# ESP32S31_RADIO register map
Vendor: Espressif; Series: ESP32-S31; File version: 3.52
Registers are 32-bit, read-write, no defined reset value unless marked. A register's access mark holds for its fields unless they carry their own. Offsets are from the block's base; [hi:lo] are bit positions.

## PHY_AGC_ORACLE — OPAQUE PHY AGC, PBus-pulse, antenna, RX-compensation, DC-memory, post-initialization and 11b-control registers recovered from complete, finite rev0 ROM/blob bodies. One physical register has one identity even when independent bodies prove different fields. Names describe their proven operation role, not an unevidenced electrical identity.
Base 0x20100000
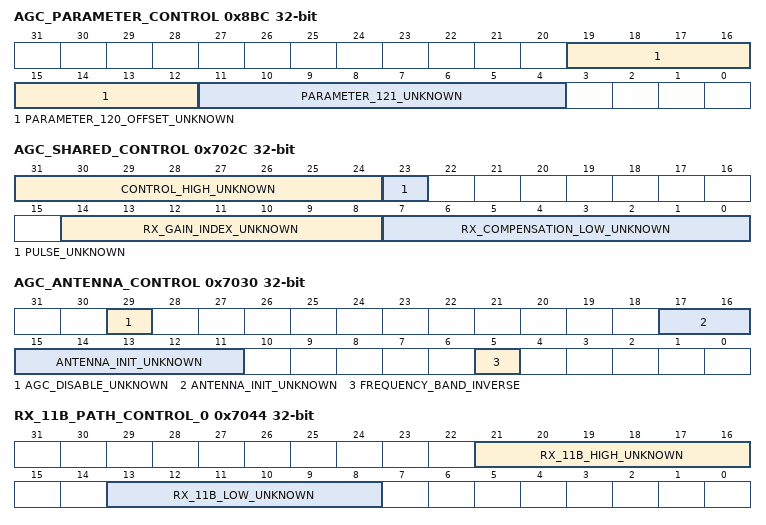
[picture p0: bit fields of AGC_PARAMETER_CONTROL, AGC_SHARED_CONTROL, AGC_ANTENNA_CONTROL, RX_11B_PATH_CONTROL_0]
0x8BC AGC_PARAMETER_CONTROL — Complete phy_agc_reg_init performs two fresh-read parameter-derived field replacements.
  [19:12] PARAMETER_120_OFFSET_UNKNOWN — Second update writes the low eight bits of parameter byte 0x120 plus 0x50 into bits 19:12.
  [11:4] PARAMETER_121_UNKNOWN — First update writes parameter byte 0x121 into bits 11:4.
0x702C AGC_SHARED_CONTROL — Shared word updated by complete phy_agc_reg_init, phy_enable_agc, phy_pbus_force_mode, phy_force_rx_gain, phy_set_rx_comp_new, and the final limit tail of phy_set_rx_gain_table.
  [31:24] CONTROL_HIGH_UNKNOWN — Complete phy_agc_reg_init and the delayed phy_pbus_force_mode tail write 0x32 into bits 31:24 before pulsing bit 23; complete phy_force_rx_gain retains its second argument to this byte without rejecting any representable image.
  [23] PULSE_UNKNOWN — Bit 23 is pulsed by complete phy_enable_agc and by the delayed tail of phy_pbus_force_mode; complete phy_force_rx_gain replaces it with the caller low bit.
  [14:8] RX_GAIN_INDEX_UNKNOWN — Bits 14:8 receive parameter byte 0x121 during AGC initialization and the final Wi-Fi RX gain index after table publication.
  [7:0] RX_COMPENSATION_LOW_UNKNOWN — Complete phy_set_rx_comp_new writes 0xed into bits 7:0.
0x7030 AGC_ANTENNA_CONTROL — Shared word updated independently by complete AGC enable/disable, antenna initialization and frequency-band selection bodies.
  [29] AGC_DISABLE_UNKNOWN — Instruction-exact AGC disable/enable gate.
  [17:11] ANTENNA_INIT_UNKNOWN — Complete phy_ant_init writes 0x34 into bits 17:11.
  [5] FREQUENCY_BAND_INVERSE — Complete phy_freq_band_reg_set writes the inverse of the caller low bit.
0x703C DC_MEMORY_CONTROL — Complete phy_dc_mem_clr sets then clears bit 20 using a fresh read before each write.
  [20] CLEAR_PULSE_UNKNOWN — Instruction-exact set/clear pulse; the vendor symbol qualifies the operation while the electrical effect remains unknown.
0x7044 RX_11B_PATH_CONTROL_0 — Complete phy_bb_agc_reg_update writes the full word; complete phy_rx_11b_opt later replaces two six-bit fields.
  [21:16] RX_11B_HIGH_UNKNOWN — Complete phy_rx_11b_opt replaces bits 21:16.
  [13:8] RX_11B_LOW_UNKNOWN — Complete phy_rx_11b_opt replaces bits 13:8.
0x7048 AGC_UPDATE_7048_OPAQUE wo — Complete phy_bb_agc_reg_update writes 0xff7da4f3.
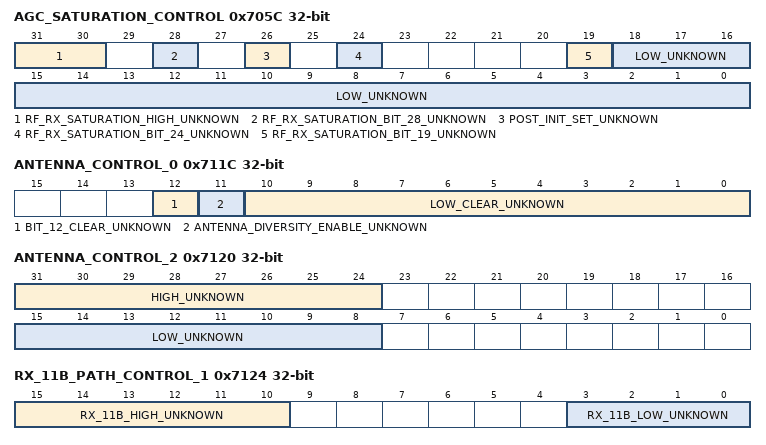
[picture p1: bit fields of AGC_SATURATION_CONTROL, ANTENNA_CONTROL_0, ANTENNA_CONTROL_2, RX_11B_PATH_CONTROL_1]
0x705C AGC_SATURATION_CONTROL — Shared word updated by complete phy_agc_reg_init, both phy_rfrx_sat_rst branches, and phy_reg_update_new.
  [31:30] RF_RX_SATURATION_HIGH_UNKNOWN — Bits 31:30 are the adjacent high pair in the discontiguous 0xd1080000 mask set or cleared by phy_rfrx_sat_rst.
  [28] RF_RX_SATURATION_BIT_28_UNKNOWN — One member of the discontiguous 0xd1080000 mask set or cleared by phy_rfrx_sat_rst.
  [26] POST_INIT_SET_UNKNOWN — Complete phy_reg_update_new sets bit 26.
  [24] RF_RX_SATURATION_BIT_24_UNKNOWN — One member of the discontiguous 0xd1080000 mask set or cleared by phy_rfrx_sat_rst.
  [19] RF_RX_SATURATION_BIT_19_UNKNOWN — One member of the discontiguous 0xd1080000 mask set or cleared by phy_rfrx_sat_rst.
  [18:0] LOW_UNKNOWN — Bits 18:0 receive 0xbb8 during AGC initialization and 0x400 or 0x800 in the two RF RX saturation phases.
0x7064 SATURATION_GAIN_LOW wo — Complete rev0 ROM phy_wifi_agc_sat_gain writes its argument here first.
  [31:0] OPAQUE_VALUE
0x7068 RF_RX_SATURATION_CONFIG wo — Complete phy_rfrx_sat_rst writes the full value 0x00000404 before either branch.
0x7094 AGC_GAIN_LIMIT_LOW — Complete phy_agc_reg_init replaces one seven-bit parameter-derived field.
  [8:2] PARAMETER_MINUS_ONE_UNKNOWN — Bits 8:2 receive the low seven bits of parameter byte 0x121 minus one.
0x70A0 RX_COMPENSATION_HIGH_CONTROL — Complete phy_set_rx_comp_new performs its second fresh-read update here.
  [31:24] RX_COMPENSATION_HIGH_UNKNOWN — Complete phy_set_rx_comp_new writes 0xed into bits 31:24.
0x70A4 CSI_DUMP_FORCE_CONTROL — Complete phy_csidump_force_lltf_cfg replaces bit fifteen from the caller low bit.
  [15] FORCE_LLTF
0x7104 RX_11B_WINDOW_CONTROL — Complete phy_bb_agc_reg_update writes the full word; phy_rx_11b_opt and phy_reg_update_new replace the same low nine-bit field with independently evidenced values.
  [8:0] WINDOW_UNKNOWN — Complete phy_rx_11b_opt writes 0x1c8 and complete phy_reg_update_new writes 0x1c0 into bits 8:0.
0x7114 SATURATION_GAIN_HIGH wo — Complete rev0 ROM phy_wifi_agc_sat_gain writes its argument here second.
  [31:0] OPAQUE_VALUE
0x711C ANTENNA_CONTROL_0 — First fresh-read update of complete phy_ant_init clears two independently evidenced field groups; complete phy_ant_dft_cfg replaces bit 11 with its caller low bit.
  [12] BIT_12_CLEAR_UNKNOWN — Complete phy_ant_init independently clears bit 12.
  [11] ANTENNA_DIVERSITY_ENABLE_UNKNOWN — Complete phy_ant_dft_cfg writes zero to disable antenna diversity and one to enable it.
    0=DISABLED (Disable the recovered antenna-diversity path.); 1=ENABLED (Enable the recovered antenna-diversity path.)
  [10:0] LOW_CLEAR_UNKNOWN — Complete phy_ant_init clears bits 10:0.
0x7120 ANTENNA_CONTROL_2 — Third fresh-read update of complete phy_ant_init writes the same value into two separated bytes.
  [31:24] HIGH_UNKNOWN — Complete phy_ant_init writes 0x1e into bits 31:24.
  [15:8] LOW_UNKNOWN — Complete phy_ant_init writes 0x1e into bits 15:8.
0x7124 RX_11B_PATH_CONTROL_1 — Complete phy_bb_agc_reg_update writes the full word; complete phy_rx_11b_opt later replaces two fields.
  [15:10] RX_11B_HIGH_UNKNOWN — Complete phy_rx_11b_opt replaces bits 15:10.
  [3:0] RX_11B_LOW_UNKNOWN — Complete phy_rx_11b_opt replaces bits 3:0.
0x7128 AGC_INIT_HIGH_CONTROL — Canonical multifunction word. Complete phy_agc_reg_init replaces the high byte with 0xd2; complete hal_init_bf later performs one volatile full-word synchronization/status read whose value is unused.
  [31:24] INIT_HIGH_UNKNOWN — Instruction-exact 0xd2 value in bits 31:24.
0x713C RX_GAIN_LIMIT_CONTROL — Shared seven-bit gain limit written by phy_agc_reg_init and the final phy_set_rx_gain_table tail.
  [24:18] RX_GAIN_LIMIT_UNKNOWN — Bits 24:18 receive parameter byte 0x121 minus one during initialization and the final Wi-Fi index capped at 0x4c after table publication.
0x78A4 AGC_UPDATE_78A4_OPAQUE wo — Complete phy_bb_agc_reg_update writes 0x0001721f.
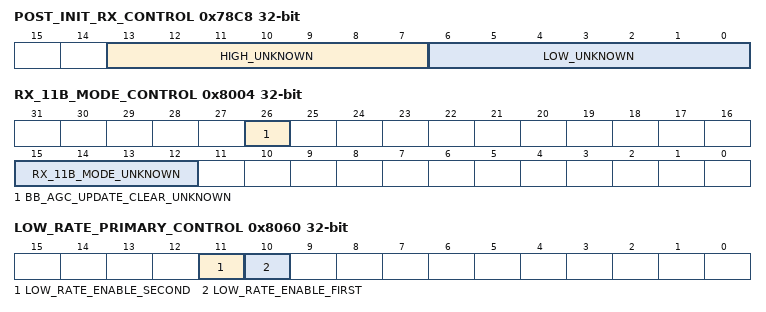
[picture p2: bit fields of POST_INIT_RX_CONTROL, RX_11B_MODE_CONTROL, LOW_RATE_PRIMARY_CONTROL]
0x78C8 POST_INIT_RX_CONTROL — Complete phy_reg_update_new performs two fresh-read field replacements in this order.
  [13:7] HIGH_UNKNOWN — Second fresh-read update replaces bits 13:7 with 0x17.
  [6:0] LOW_UNKNOWN — First fresh-read update replaces bits 6:0 with 0x17.
0x7D4C FTM_CONTROL — Complete phy_set_ftm_en replaces bit zero with its one-bit argument.
  [0] ENABLE — One-bit FTM enable argument.
0x8004 RX_11B_MODE_CONTROL — Complete phy_bb_agc_reg_update clears bit 26; complete phy_rx_11b_opt replaces bits 15:12.
  [26] BB_AGC_UPDATE_CLEAR_UNKNOWN — Complete phy_bb_agc_reg_update clears bit 26.
  [15:12] RX_11B_MODE_UNKNOWN — Complete phy_rx_11b_opt replaces bits 15:12.
0x8010 AGC_UPDATE_8010_OPAQUE wo — Complete phy_bb_agc_reg_update writes 0x000852a1.
0x8018 AGC_UPDATE_8018_OPAQUE wo — Complete phy_bb_agc_reg_update writes 0x00600030.
0x801C AGC_UPDATE_801C_OPAQUE wo — Complete phy_bb_agc_reg_update writes 0x010000a0.
0x8020 AGC_UPDATE_8020_OPAQUE wo — Complete phy_bb_agc_reg_update writes 0x00000180.
0x8028 AGC_UPDATE_8028_OPAQUE wo — Complete phy_bb_agc_reg_update writes 0xc0403020.
0x802C AGC_UPDATE_802C_OPAQUE wo — Complete phy_bb_agc_reg_update writes 0x01000080.
0x8060 LOW_RATE_PRIMARY_CONTROL — Complete phy_enable_low_rate sets bits 10 and 11 through separate fresh-read RMW edges; complete phy_disable_low_rate clears them in the same order; complete phy_rx11blr_cfg replaces both with its caller low bit.
  [11] LOW_RATE_ENABLE_SECOND — Second independently updated low-rate enable bit.
  [10] LOW_RATE_ENABLE_FIRST — First independently updated low-rate enable bit.
0x8070 AGC_UPDATE_8070_OPAQUE wo — Complete phy_bb_agc_reg_update writes 0x000008c7.
0x8078 AGC_UPDATE_8078_CONTROL — Complete phy_bb_agc_reg_update sets bits 22:20.
  [22:20] BB_AGC_UPDATE_SET_UNKNOWN — Complete phy_bb_agc_reg_update sets all three bits.
0x807C LOW_RATE_SECONDARY_CONTROL — Third and final fresh-read RMW in the complete low-rate leaves and phy_rx11blr_cfg.
  [11] LOW_RATE_ENABLE — Set by complete phy_enable_low_rate and cleared by complete phy_disable_low_rate.
